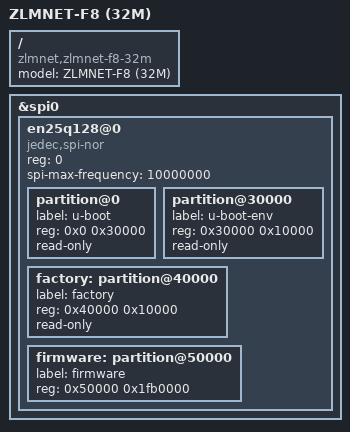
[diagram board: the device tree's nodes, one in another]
/dts-v1/;

#include "ZLMNET-F8.dtsi"

/ {
	compatible = "zlmnet,zlmnet-f8-32m", "zlmnet,zlmnet-f8", "ralink,mt7620a-soc";
	model = "ZLMNET-F8 (32M)";
};

&spi0 {
	status = "okay";

	en25q128@0 {
		#address-cells = <1>;
		#size-cells = <1>;
		compatible = "jedec,spi-nor";
		reg = <0>;
		spi-max-frequency = <10000000>;

		partition@0 {
			label = "u-boot";
			reg = <0x0 0x30000>;
			read-only;
		};

		partition@30000 {
			label = "u-boot-env";
			reg = <0x30000 0x10000>;
			read-only;
		};

		factory: partition@40000 {
			label = "factory";
			reg = <0x40000 0x10000>;
			read-only;
		};

		firmware: partition@50000 {
			label = "firmware";
			reg = <0x50000 0x1fb0000>;
		};
	};
};
